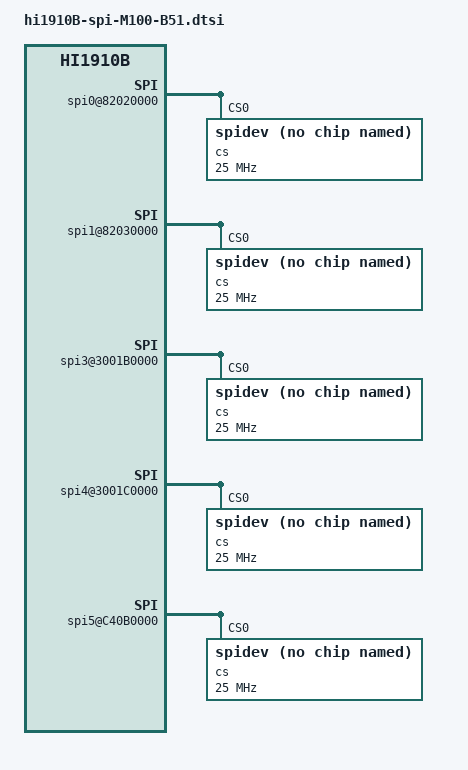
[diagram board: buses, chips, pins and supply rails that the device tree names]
	spi0@82020000 {
		compatible = "hisilicon,udrv_spi";
		#address-cells = <1>;
		#size-cells = <0>;
		num-cs = <1>; /* 支持cs片选个数量 */
		bus-num = <0>; /* spi控制器id */
		clk-freq = <150000000>; /* 时钟频率 */
		reg = <0x0 0x82020000 0 0x10000>;
		interrupts = <0x0 161 0x4>;
		cs@0 {
			compatible = "rohm,dh2228fv";
			reg = <0>; /* cs片选id */
			spi-max-frequency = <25000000>;
		};	
	};

	spi1@82030000 {
		compatible = "hisilicon,udrv_spi";
		#address-cells = <1>;
		#size-cells = <0>;
		num-cs = <1>; /* 支持cs片选个数量 */
		bus-num = <1>; /* spi控制器id */
		clk-freq = <150000000>; /* 时钟频率 */
		reg = <0x0 0x82030000 0 0x10000>;
		interrupts = <0x0 162 0x4>;
		cs@0 {
			compatible = "rohm,dh2228fv";
			reg = <0>; /* cs片选id */
			spi-max-frequency = <25000000>;
		};
	};

	spi3@3001B0000 {
		compatible = "hisilicon,udrv_spi";
		#address-cells = <1>;
		#size-cells = <0>;
		num-cs = <1>; /* 支持cs片选个数量 */
		bus-num = <3>; /* spi控制器id */
		clk-freq = <150000000>; /* 时钟频率 */
		reg = <0x3 0x1B0000 0 0x10000>;
		interrupts = <0x0 251 0x4>;
		// To enable the SPI function, uncomment the following two lines and comment the pinctrl configuration of the I2C 0 1
		// pinctrl-names = "default";
		// pinctrl-0 = <&iomg000_pmx_func &iomg001_pmx_func &iomg002_pmx_func &iomg003_pmx_func>;
		cs@0 {
			compatible = "rohm,dh2228fv";
			reg = <0>; /* cs片选id */
			spi-max-frequency = <25000000>;
		};
	};

	spi4@3001C0000 {
		compatible = "hisilicon,udrv_spi";
		#address-cells = <1>;
		#size-cells = <0>;
		num-cs = <1>; /* 支持cs片选个数量 */
		bus-num = <4>; /* spi控制器id */
		clk-freq = <150000000>; /* 时钟频率 */
		reg = <0x3 0x1C0000 0 0x10000>;
		interrupts = <0x0 252 0x4>;
		// To enable the SPI function, uncomment the following two lines and comment the pinctrl configuration of the I2C 2 3
		// pinctrl-names = "default";
		// pinctrl-0 = <&iomg004_pmx_func &iomg005_pmx_func &iomg006_pmx_func &iomg007_pmx_func>;
		cs@0 {
			compatible = "rohm,dh2228fv";
			reg = <0>; /* cs片选id */
			spi-max-frequency = <25000000>;
		};
	};

	spi5@C40B0000 {
		compatible = "hisilicon,udrv_spi";
		#address-cells = <1>;
		#size-cells = <0>;
		num-cs = <1>; /* 支持cs片选个数量 */
		bus-num = <5>; /* spi控制器id */
		clk-freq = <150000000>; /* 时钟频率 */
		reg = <0x0 0xC40B0000 0 0x10000>;
		interrupts = <0x0 163 0x4>;
		cs@0 {
			compatible = "rohm,dh2228fv";
			reg = <0>; /* cs片选id */
			spi-max-frequency = <25000000>;
		};
	};
    
//	spi6@82040000 {
//		compatible = "hisilicon,udrv_spi";
//		#address-cells = <1>;
//		#size-cells = <0>;
//		num-cs = <1>; /* 支持cs片选个数量 */
//		bus-num = <6>; /* spi控制器id */
//		clk-freq = <150000000>; /* 时钟频率 */
//		reg = <0x0 0x82040000 0 0x10000>;
//		interrupts = <0x0 164 0x4>;
//		cs@0 {
//			compatible = "rohm,dh2228fv";
//			reg = <0>; /* cs片选id */
//			spi-max-frequency = <25000000>;
//		};
//	};
    
	//spi7@401060000 {
		//compatible = "hisilicon,udrv_spi";
		//#address-cells = <1>;
		//#size-cells = <0>;
		//num-cs = <1>; /* 支持cs片选个数量 */
		//bus-num = <7>; /* spi控制器id */
		//clk-freq = <150000000>; /* 时钟频率 */
		//reg = <0x4 0x1060000 0 0x10000>;
		//interrupts = <0x0 281 0x4>;
		//cs@0 {
			//compatible = "rohm,dh2228fv";
			//reg = <0>; /* cs片选id */
			//spi-max-frequency = <25000000>;
		//};
	//};
    
	//spi8@401070000 {
		//compatible = "hisilicon,udrv_spi";
		//#address-cells = <1>;
		//#size-cells = <0>;
		//num-cs = <1>; /* 支持cs片选个数量 */
		//bus-num = <8>; /* spi控制器id */
		//clk-freq = <150000000>; /* 时钟频率 */
		//reg = <0x4 0x1070000 0 0x10000>;
		//interrupts = <0x0 282 0x4>;
		//cs@0 {
			//compatible = "rohm,dh2228fv";
			//reg = <0>; /* cs片选id */
			//spi-max-frequency = <25000000>;
		//};
	//};
    
